# CY8C5888LTI_LP097 register map
File version: 0.1
Registers are 8-bit, read-write, no defined reset value unless marked. A register's access mark holds for its fields unless they carry their own. Offsets are from the block's base; [hi:lo] are bit positions; 'fields as' and 'values as' point back to an identical list.

## Timeout_1
Base 0x00000000
0x40006504 Timeout_1_COUNTER 16-bit — UDB.A0 - Current Down Counter Value
0x40006524 Timeout_1_PERIOD 16-bit — UDB.D0 - Assigned Period
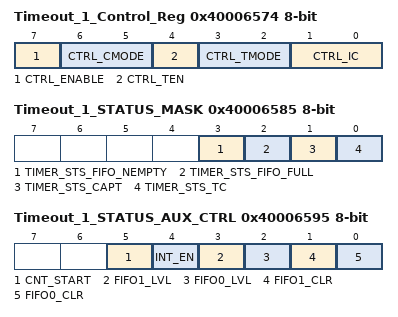
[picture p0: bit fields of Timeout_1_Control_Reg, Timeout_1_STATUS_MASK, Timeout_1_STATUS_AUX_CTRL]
0x40006574 Timeout_1_Control_Reg — UDB Control Register - Assigned Control Register Value
  [7] CTRL_ENABLE — Enable the Timer
  [6:5] CTRL_CMODE — Capture Mode
  [4] CTRL_TEN — Trigger Enable Bit
  [3:2] CTRL_TMODE — Trigger Mode
  [1:0] CTRL_IC — Interrupt Count
0x40006585 Timeout_1_STATUS_MASK — UDB Status bits Interrupt Mask Enable Register
  [3] TIMER_STS_FIFO_NEMPTY ro — FIFO Empty status
  [2] TIMER_STS_FIFO_FULL ro — FIFO Full Status
  [1] TIMER_STS_CAPT ro — Enables the Interrupt on Capture
  [0] TIMER_STS_TC ro — Enables the Interrupt on TC
0x40006595 Timeout_1_STATUS_AUX_CTRL — UDB Auxilliary Control Register
  [5] CNT_START — FIFO0 clear
    0=E_CNT_START0 (Disable counter); 1=E_CNT_START1 (Enable counter)
  [4] INT_EN
    0=E_INT_EN0 (Interrupt disabled); 1=E_INT_EN1 (Interrupt enabled)
  [3] FIFO1_LVL — FIFO level
    0=E_FIFO_LVL_0 (FIFO LVL: input mode: FIFO not full; output mode: FIFO not empty); 1=E_FIFO_LVL_1 (FIFO LVL: input mode: FIFO at least 1/2 empty; output mode: FIFO at least 1/2 full)
  [2] FIFO0_LVL — FIFO level
    values as FIFO1_LVL
  [1] FIFO1_CLR — FIFO1 clear
    0=E_FIFO_CLR_0 (Normal FIFO operation); 1=E_FIFO_CLR_1 (Clear FIFO state)
  [0] FIFO0_CLR — FIFO0 clear
    values as FIFO1_CLR

## Timeout_2
Base 0x00000000
0x4000640E Timeout_2_COUNTER 16-bit — UDB.A0 - Current Down Counter Value
0x4000642E Timeout_2_PERIOD 16-bit — UDB.D0 - Assigned Period
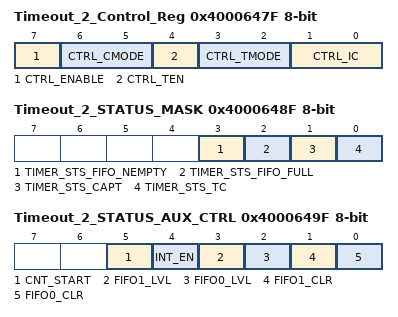
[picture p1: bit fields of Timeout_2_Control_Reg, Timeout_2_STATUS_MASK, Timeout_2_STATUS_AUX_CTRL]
0x4000647F Timeout_2_Control_Reg — UDB Control Register - Assigned Control Register Value
  [7] CTRL_ENABLE — Enable the Timer
  [6:5] CTRL_CMODE — Capture Mode
  [4] CTRL_TEN — Trigger Enable Bit
  [3:2] CTRL_TMODE — Trigger Mode
  [1:0] CTRL_IC — Interrupt Count
0x4000648F Timeout_2_STATUS_MASK — UDB Status bits Interrupt Mask Enable Register
  [3] TIMER_STS_FIFO_NEMPTY ro — FIFO Empty status
  [2] TIMER_STS_FIFO_FULL ro — FIFO Full Status
  [1] TIMER_STS_CAPT ro — Enables the Interrupt on Capture
  [0] TIMER_STS_TC ro — Enables the Interrupt on TC
0x4000649F Timeout_2_STATUS_AUX_CTRL — UDB Auxilliary Control Register
  [5] CNT_START — FIFO0 clear
    0=E_CNT_START0 (Disable counter); 1=E_CNT_START1 (Enable counter)
  [4] INT_EN
    0=E_INT_EN0 (Interrupt disabled); 1=E_INT_EN1 (Interrupt enabled)
  [3] FIFO1_LVL — FIFO level
    0=E_FIFO_LVL_0 (FIFO LVL: input mode: FIFO not full; output mode: FIFO not empty); 1=E_FIFO_LVL_1 (FIFO LVL: input mode: FIFO at least 1/2 empty; output mode: FIFO at least 1/2 full)
  [2] FIFO0_LVL — FIFO level
    values as FIFO1_LVL
  [1] FIFO1_CLR — FIFO1 clear
    0=E_FIFO_CLR_0 (Normal FIFO operation); 1=E_FIFO_CLR_1 (Clear FIFO state)
  [0] FIFO0_CLR — FIFO0 clear
    values as FIFO1_CLR

## QuadDec_1
Base 0x00000000
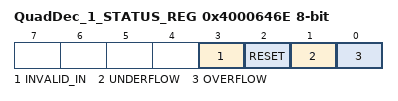
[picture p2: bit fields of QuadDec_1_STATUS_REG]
0x4000646E QuadDec_1_STATUS_REG — Quadrature Decoder Status Register
  [3] INVALID_IN ro — Invalid state transition on the A and B inputs
  [2] RESET ro — Counter Reset due index
  [1] UNDERFLOW ro — Counter underflow
  [0] OVERFLOW ro — Counter overflow
0x40006508 QuadDec_1_Cnt16_COUNTER 16-bit — Counter value

## QuadDec_1_Cnt16
Base 0x00000000; alternate view of QuadDec_1
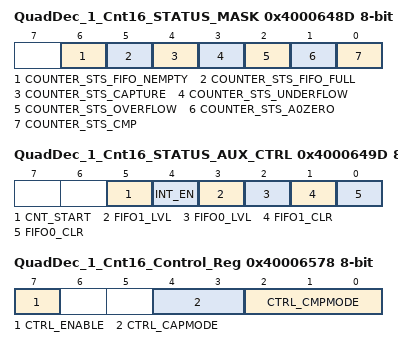
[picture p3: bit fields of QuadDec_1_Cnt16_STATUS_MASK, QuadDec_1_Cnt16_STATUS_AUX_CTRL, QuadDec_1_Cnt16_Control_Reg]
0x4000648D QuadDec_1_Cnt16_STATUS_MASK — UDB Status bits Interrupt Mask Enable Register
  [6] COUNTER_STS_FIFO_NEMPTY — FIFO Not Empty Status
  [5] COUNTER_STS_FIFO_FULL — FIFO Full Status
  [4] COUNTER_STS_CAPTURE — Capture Status
  [3] COUNTER_STS_UNDERFLOW — Underflow status
  [2] COUNTER_STS_OVERFLOW — Overflow status
  [1] COUNTER_STS_A0ZERO — A0 Zero ouput status
  [0] COUNTER_STS_CMP — Compare output status
0x4000649D QuadDec_1_Cnt16_STATUS_AUX_CTRL — UDB Auxilliary Control Register
  [5] CNT_START — FIFO0 clear
    0=E_CNT_START0 (Disable counter); 1=E_CNT_START1 (Enable counter)
  [4] INT_EN
    0=E_INT_EN0 (Interrupt disabled); 1=E_INT_EN1 (Interrupt enabled)
  [3] FIFO1_LVL — FIFO level
    0=E_FIFO_LVL_0 (FIFO LVL: input mode: FIFO not full; output mode: FIFO not empty); 1=E_FIFO_LVL_1 (FIFO LVL: input mode: FIFO at least 1/2 empty; output mode: FIFO at least 1/2 full)
  [2] FIFO0_LVL — FIFO level
    values as FIFO1_LVL
  [1] FIFO1_CLR — FIFO1 clear
    0=E_FIFO_CLR_0 (Normal FIFO operation); 1=E_FIFO_CLR_1 (Clear FIFO state)
  [0] FIFO0_CLR — FIFO0 clear
    values as FIFO1_CLR
0x40006508 QuadDec_1_Cnt16_COUNTER 16-bit — UDB.A0 - Current Counter Value
0x40006528 QuadDec_1_Cnt16_PERIOD 16-bit — UDB.D0 - Assigned Period
0x40006538 QuadDec_1_Cnt16_COMPARE 16-bit — UDB.D1 - Assigned Compare Value
0x40006578 QuadDec_1_Cnt16_Control_Reg — UDB Control Register - Assigned Control Register Value
  [7] CTRL_ENABLE — Enable Counter
  [4:3] CTRL_CAPMODE — Capture mode
  [2:0] CTRL_CMPMODE — Compare mode
